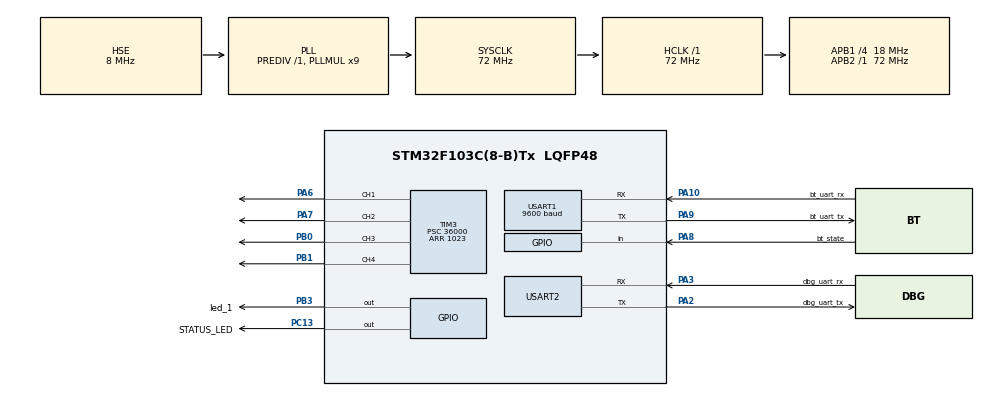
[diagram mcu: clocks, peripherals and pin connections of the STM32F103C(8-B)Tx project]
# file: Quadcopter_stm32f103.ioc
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Mcu.Family=STM32F1
Mcu.Name=STM32F103C(8-B)Tx
Mcu.Package=LQFP48
NVIC.PriorityGroup=NVIC_PRIORITYGROUP_4
NVIC.TIM3_IRQn=true\:0\:0\:false\:false\:true\:true\:true
NVIC.USART1_IRQn=true\:0\:0\:false\:false\:true\:true\:true
NVIC.USART2_IRQn=true\:0\:0\:false\:false\:true\:true\:true
PA10.GPIO_Label=bt_uart_rx
PA10.Mode=Asynchronous
PA10.Signal=USART1_RX
PA13.Mode=Serial_Wire
PA13.Signal=SYS_JTMS-SWDIO
PA14.Mode=Serial_Wire
PA14.Signal=SYS_JTCK-SWCLK
PA2.GPIO_Label=dbg_uart_tx
PA2.Mode=Asynchronous
PA2.Signal=USART2_TX
PA3.GPIO_Label=dbg_uart_rx
PA3.Mode=Asynchronous
PA3.Signal=USART2_RX
PA6.Signal=S_TIM3_CH1
PA7.Signal=S_TIM3_CH2
PA8.GPIO_Label=bt_state
PA8.Signal=GPIO_Input
PA9.GPIO_Label=bt_uart_tx
PA9.Mode=Asynchronous
PA9.Signal=USART1_TX
PB0.Signal=S_TIM3_CH3
PB1.Signal=S_TIM3_CH4
PB3.GPIO_Label=led_1
PB3.PinState=GPIO_PIN_RESET
PB3.Signal=GPIO_Output
PC13-TAMPER-RTC.GPIO_Label=STATUS_LED
PC13-TAMPER-RTC.PinState=GPIO_PIN_RESET
PC13-TAMPER-RTC.Signal=GPIO_Output
PD0-OSC_IN.Mode=HSE-External-Oscillator
PD0-OSC_IN.Signal=RCC_OSC_IN
PD1-OSC_OUT.Mode=HSE-External-Oscillator
PD1-OSC_OUT.Signal=RCC_OSC_OUT
ProjectManager.HeapSize=0x200
ProjectManager.StackSize=0x400
ProjectManager.TargetToolchain=Makefile
RCC.AHBFreq_Value=72000000
RCC.APB1CLKDivider=RCC_HCLK_DIV4
RCC.APB1Freq_Value=18000000
RCC.APB1TimFreq_Value=36000000
RCC.APB2Freq_Value=72000000
RCC.APB2TimFreq_Value=72000000
RCC.HCLKFreq_Value=72000000
RCC.PLLMUL=RCC_PLL_MUL9
RCC.PLLSourceVirtual=RCC_PLLSOURCE_HSE
RCC.SYSCLKFreq_VALUE=72000000
RCC.SYSCLKSource=RCC_SYSCLKSOURCE_PLLCLK
RCC.USBFreq_Value=72000000
SH.S_TIM3_CH1.0=TIM3_CH1,PWM Generation1 CH1
SH.S_TIM3_CH2.0=TIM3_CH2,PWM Generation2 CH2
SH.S_TIM3_CH3.0=TIM3_CH3,PWM Generation3 CH3
SH.S_TIM3_CH4.0=TIM3_CH4,PWM Generation4 CH4
TIM3.Channel-PWM\ Generation1\ CH1=TIM_CHANNEL_1
TIM3.Channel-PWM\ Generation2\ CH2=TIM_CHANNEL_2
TIM3.Channel-PWM\ Generation3\ CH3=TIM_CHANNEL_3
TIM3.Channel-PWM\ Generation4\ CH4=TIM_CHANNEL_4
TIM3.Period=1023
TIM3.Prescaler=36000
USART1.BaudRate=9600
USART1.VirtualMode=VM_ASYNC
USART2.VirtualMode=VM_ASYNC
VP_TIM3_VS_ClockSourceINT.Mode=Internal
board=custom

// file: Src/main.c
/* USER CODE BEGIN Header */
/**
  ******************************************************************************
  * @file           : main.c
  * @brief          : Main program body
  ******************************************************************************
  * @attention
  *
  * <h2><center>&copy; Copyright (c) 2020 STMicroelectronics.
  * All rights reserved.</center></h2>
  *
  * This software component is licensed by ST under BSD 3-Clause license,
  * the "License"; You may not use this file except in compliance with the
  * License. You may obtain a copy of the License at:
  *                        opensource.org/licenses/BSD-3-Clause
  *
  ******************************************************************************
  */
/* USER CODE END Header */

#include "main.h"

/* USER CODE BEGIN Includes */
#include "my_main.h"
#include "dbg_uart.h"
#include "bt_uart.h"

/* USER CODE END Includes */

TIM_HandleTypeDef htim3;

UART_HandleTypeDef huart1;
UART_HandleTypeDef huart2;

void SystemClock_Config(void);
static void MX_GPIO_Init(void);
static void MX_TIM3_Init(void);
static void MX_USART1_UART_Init(void);
static void MX_USART2_UART_Init(void);

int main(void)
{

  /* MCU Configuration--------------------------------------------------------*/

  /* Reset of all peripherals, Initializes the Flash interface and the Systick. */
  HAL_Init();

  /* Configure the system clock */
  SystemClock_Config();

  /* Initialize all configured peripherals */
  MX_GPIO_Init();
  MX_TIM3_Init();
  MX_USART1_UART_Init();
  MX_USART2_UART_Init();

  /* Infinite loop */
  /* USER CODE BEGIN WHILE */
  bt_uart_start_receiving();
  my_main();
  while (1)
  {
    /* USER CODE END WHILE */

  }
}

void SystemClock_Config(void)
{
  RCC_OscInitTypeDef RCC_OscInitStruct = {0};
  RCC_ClkInitTypeDef RCC_ClkInitStruct = {0};

  /** Initializes the CPU, AHB and APB busses clocks
  */
  RCC_OscInitStruct.OscillatorType = RCC_OSCILLATORTYPE_HSE;
  RCC_OscInitStruct.HSEState = RCC_HSE_ON;
  RCC_OscInitStruct.HSEPredivValue = RCC_HSE_PREDIV_DIV1;
  RCC_OscInitStruct.HSIState = RCC_HSI_ON;
  RCC_OscInitStruct.PLL.PLLState = RCC_PLL_ON;
  RCC_OscInitStruct.PLL.PLLSource = RCC_PLLSOURCE_HSE;
  RCC_OscInitStruct.PLL.PLLMUL = RCC_PLL_MUL9;
  if (HAL_RCC_OscConfig(&RCC_OscInitStruct) != HAL_OK)
  {
    Error_Handler();
  }
  /** Initializes the CPU, AHB and APB busses clocks
  */
  RCC_ClkInitStruct.ClockType = RCC_CLOCKTYPE_HCLK|RCC_CLOCKTYPE_SYSCLK
                              |RCC_CLOCKTYPE_PCLK1|RCC_CLOCKTYPE_PCLK2;
  RCC_ClkInitStruct.SYSCLKSource = RCC_SYSCLKSOURCE_PLLCLK;
  RCC_ClkInitStruct.AHBCLKDivider = RCC_SYSCLK_DIV1;
  RCC_ClkInitStruct.APB1CLKDivider = RCC_HCLK_DIV4;
  RCC_ClkInitStruct.APB2CLKDivider = RCC_HCLK_DIV1;

  if (HAL_RCC_ClockConfig(&RCC_ClkInitStruct, FLASH_LATENCY_2) != HAL_OK)
  {
    Error_Handler();
  }
}

static void MX_TIM3_Init(void)
{

  TIM_ClockConfigTypeDef sClockSourceConfig = {0};
  TIM_MasterConfigTypeDef sMasterConfig = {0};
  TIM_OC_InitTypeDef sConfigOC = {0};

  htim3.Instance = TIM3;
  htim3.Init.Prescaler = 36000;
  htim3.Init.CounterMode = TIM_COUNTERMODE_UP;
  htim3.Init.Period = 1023;
  htim3.Init.ClockDivision = TIM_CLOCKDIVISION_DIV1;
  htim3.Init.AutoReloadPreload = TIM_AUTORELOAD_PRELOAD_DISABLE;
  if (HAL_TIM_Base_Init(&htim3) != HAL_OK)
  {
    Error_Handler();
  }
  sClockSourceConfig.ClockSource = TIM_CLOCKSOURCE_INTERNAL;
  if (HAL_TIM_ConfigClockSource(&htim3, &sClockSourceConfig) != HAL_OK)
  {
    Error_Handler();
  }
  if (HAL_TIM_PWM_Init(&htim3) != HAL_OK)
  {
    Error_Handler();
  }
  sMasterConfig.MasterOutputTrigger = TIM_TRGO_RESET;
  sMasterConfig.MasterSlaveMode = TIM_MASTERSLAVEMODE_DISABLE;
  if (HAL_TIMEx_MasterConfigSynchronization(&htim3, &sMasterConfig) != HAL_OK)
  {
    Error_Handler();
  }
  sConfigOC.OCMode = TIM_OCMODE_PWM1;
  sConfigOC.Pulse = 0;
  sConfigOC.OCPolarity = TIM_OCPOLARITY_HIGH;
  sConfigOC.OCFastMode = TIM_OCFAST_DISABLE;
  if (HAL_TIM_PWM_ConfigChannel(&htim3, &sConfigOC, TIM_CHANNEL_1) != HAL_OK)
  {
    Error_Handler();
  }
  if (HAL_TIM_PWM_ConfigChannel(&htim3, &sConfigOC, TIM_CHANNEL_2) != HAL_OK)
  {
    Error_Handler();
  }
  if (HAL_TIM_PWM_ConfigChannel(&htim3, &sConfigOC, TIM_CHANNEL_3) != HAL_OK)
  {
    Error_Handler();
  }
  if (HAL_TIM_PWM_ConfigChannel(&htim3, &sConfigOC, TIM_CHANNEL_4) != HAL_OK)
  {
    Error_Handler();
  }
  HAL_TIM_MspPostInit(&htim3);

}

static void MX_USART1_UART_Init(void)
{

  huart1.Instance = USART1;
  huart1.Init.BaudRate = 9600;
  huart1.Init.WordLength = UART_WORDLENGTH_8B;
  huart1.Init.StopBits = UART_STOPBITS_1;
  huart1.Init.Parity = UART_PARITY_NONE;
  huart1.Init.Mode = UART_MODE_TX_RX;
  huart1.Init.HwFlowCtl = UART_HWCONTROL_NONE;
  huart1.Init.OverSampling = UART_OVERSAMPLING_16;
  if (HAL_UART_Init(&huart1) != HAL_OK)
  {
    Error_Handler();
  }

}

static void MX_USART2_UART_Init(void)
{

  huart2.Instance = USART2;
  huart2.Init.BaudRate = 115200;
  huart2.Init.WordLength = UART_WORDLENGTH_8B;
  huart2.Init.StopBits = UART_STOPBITS_1;
  huart2.Init.Parity = UART_PARITY_NONE;
  huart2.Init.Mode = UART_MODE_TX_RX;
  huart2.Init.HwFlowCtl = UART_HWCONTROL_NONE;
  huart2.Init.OverSampling = UART_OVERSAMPLING_16;
  if (HAL_UART_Init(&huart2) != HAL_OK)
  {
    Error_Handler();
  }

}

static void MX_GPIO_Init(void)
{
  GPIO_InitTypeDef GPIO_InitStruct = {0};

  /* GPIO Ports Clock Enable */
  __HAL_RCC_GPIOC_CLK_ENABLE();
  __HAL_RCC_GPIOD_CLK_ENABLE();
  __HAL_RCC_GPIOA_CLK_ENABLE();
  __HAL_RCC_GPIOB_CLK_ENABLE();

  /*Configure GPIO pin Output Level */
  HAL_GPIO_WritePin(STATUS_LED_GPIO_Port, STATUS_LED_Pin, GPIO_PIN_RESET);

  /*Configure GPIO pin Output Level */
  HAL_GPIO_WritePin(led_1_GPIO_Port, led_1_Pin, GPIO_PIN_RESET);

  /*Configure GPIO pin : STATUS_LED_Pin */
  GPIO_InitStruct.Pin = STATUS_LED_Pin;
  GPIO_InitStruct.Mode = GPIO_MODE_OUTPUT_PP;
  GPIO_InitStruct.Pull = GPIO_NOPULL;
  GPIO_InitStruct.Speed = GPIO_SPEED_FREQ_LOW;
  HAL_GPIO_Init(STATUS_LED_GPIO_Port, &GPIO_InitStruct);

  /*Configure GPIO pin : bt_state_Pin */
  GPIO_InitStruct.Pin = bt_state_Pin;
  GPIO_InitStruct.Mode = GPIO_MODE_INPUT;
  GPIO_InitStruct.Pull = GPIO_NOPULL;
  HAL_GPIO_Init(bt_state_GPIO_Port, &GPIO_InitStruct);

  /*Configure GPIO pin : led_1_Pin */
  GPIO_InitStruct.Pin = led_1_Pin;
  GPIO_InitStruct.Mode = GPIO_MODE_OUTPUT_PP;
  GPIO_InitStruct.Pull = GPIO_NOPULL;
  GPIO_InitStruct.Speed = GPIO_SPEED_FREQ_LOW;
  HAL_GPIO_Init(led_1_GPIO_Port, &GPIO_InitStruct);

}

void Error_Handler(void)
{
}

/************************ (C) COPYRIGHT STMicroelectronics *****END OF FILE****/
